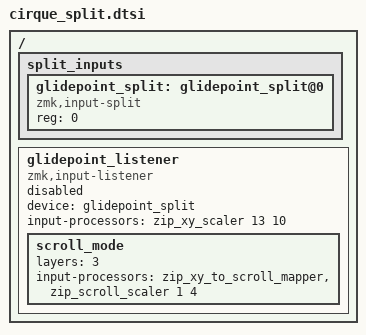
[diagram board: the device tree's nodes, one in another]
#include <dt-bindings/zmk/input_transform.h>
#include <input/processors.dtsi>

/ {
    split_inputs {
        #address-cells = <1>;
        #size-cells = <0>;

        glidepoint_split: glidepoint_split@0 {
            compatible = "zmk,input-split";
            reg = <0>;
        };
    };

    glidepoint_listener: glidepoint_listener {
        compatible = "zmk,input-listener";
        status = "disabled";
        device = <&glidepoint_split>;
        input-processors = <&zip_xy_scaler 13 10>;

        scroll_mode {
            layers = <3>;
            input-processors = <&zip_xy_to_scroll_mapper &zip_scroll_scaler 1 4>;
        };
    };
};
